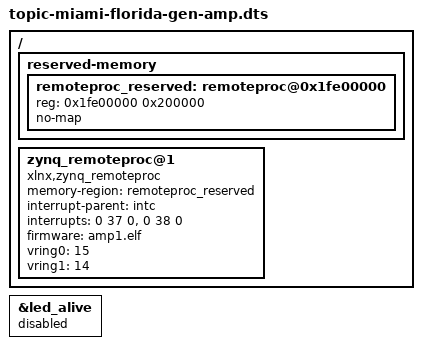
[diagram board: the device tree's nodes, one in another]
/* Devicetree for use with Asymetric Multiple Processing */
/dts-v1/;
/include/ "topic-miami-florida-gen.dtsi"

/ {
	reserved-memory {
		#address-cells = <1>;
		#size-cells = <1>;
		ranges;

		/* Reserve the top 2 MB of the 0.5GB DDR RAM */
		remoteproc_reserved: remoteproc@0x1fe00000 {
			reg = <0x1fe00000 0x200000>;
			no-map; /* For dma_declare_coherent_memory() */
		};
	};

	/* Boot CPU1 with AMP software, using reserved memory for firmware */
	zynq_remoteproc@1 {
		compatible = "xlnx,zynq_remoteproc";
		memory-region = <&remoteproc_reserved>;
		interrupt-parent = <&intc>;
		interrupts = <0 37 0>, <0 38 0>;
		firmware = "amp1.elf";
		/* vring0 is the ipino */
		vring0 = <15>;
		vring1 = <14>;
	};
};

/* Remove the "alive" LED so it can be controlled by the AMP firmware */
&led_alive {
	status = "disabled";
};
